# V32F20x_CM0 register map
File version: 1.0.1
CPU: CM0 r0p0, little endian, no MPU, no FPU, 2 interrupt priority bits
Registers are 32-bit, read-write, reset 0x0 unless marked. A register's access mark holds for its fields unless they carry their own. Offsets are from the block's base; [hi:lo] are bit positions; {n}, {i} and the like mark numbered series.

## CRYPT — CRYPT Peripheral Interface
Base 0x4120C000
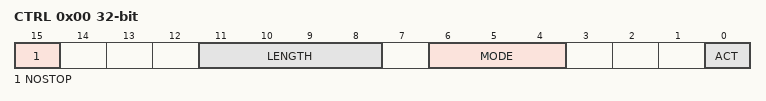
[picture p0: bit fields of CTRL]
0x00 CTRL — CRYPT control register.
  [15] NOSTOP — This register is used to control if the CPU will be stop by CRYPT engine when the CRYPT engine is busy and CPU read or write CRYPT engine register
  [11:8] LENGTH — This bit is used to control the VLI length of current operation
  [6:4] MODE — This register controls the operation mode of crypt engine
  [0] ACT — Write 1 to this bit will start an operation specified in the MODE register
0x04 PTRA — CRYPT pointer A register.
  [15:0] PTRA — This is the PTRA register of CRYPT controller
0x08 PTRB — CRYPT pointer B register.
  [15:0] PTRB — This is the PTRB register of CRYPT controller.
0x0C PTRO — CRYPT pointer O register.
  [15:0] PTRO — This is the PTRO register of CRYPT controller.
0x10 CARRY ro — CRYPT carry/borrow bit register.
  [0] CARRY — This bit represent the carry bit after add operation is done

## RETRAM — RETRAM Peripheral Interface
Base 0x41100000
{0x0+4i} RAM{i} (i=0..63) — PMU 32 bits Retention RAM 0~63
  [31:0] RAM — There is a 256 bytes 64x32 SRAM embedded in the PMU controller

## COMP — COMP Peripheral Interface
Base 0x41101800
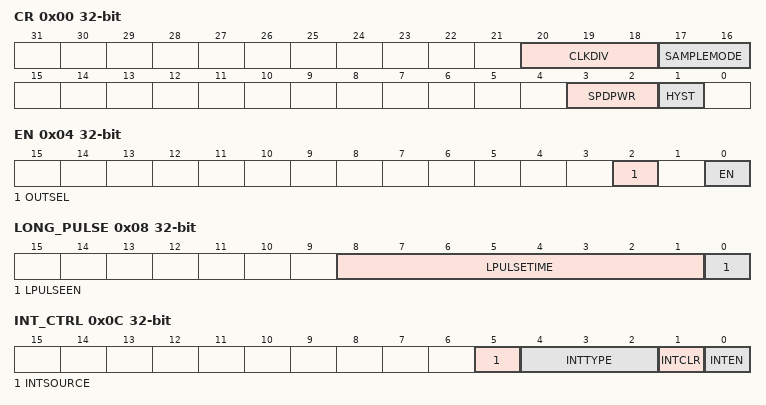
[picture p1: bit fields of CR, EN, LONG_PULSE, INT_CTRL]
0x00 CR — Control Register
  [20:18] CLKDIV — Filter clock divider
  [17:16] SAMPLEMODE — Control the filtering of the Analog Comparator output
  [3:2] SPDPWR — 00 Low speed Ultra low power Power consumption 2
  [1] HYST — 0: No Hysteresis Voltage
0x04 EN — Enable Register
  [2] OUTSEL — Comparator comparison select
  [0] EN — Enable Comparator
0x08 LONG_PULSE — Long pulse mode register
  [8:1] LPULSETIME — Desired time period of the long pulse.
  [0] LPULSEEN — Enable long pulse mode
0x0C INT_CTRL — Interrupt Control
  [5] INTSOURCE — Select which Analog comparator output filtered or unfiltered is used for interrupt detection
  [4:2] INTTYPE — Comparator interrupt type selector.
  [1] INTCLR — COMP interrupt clear.
  [0] INTEN — COMP interrupt enable.
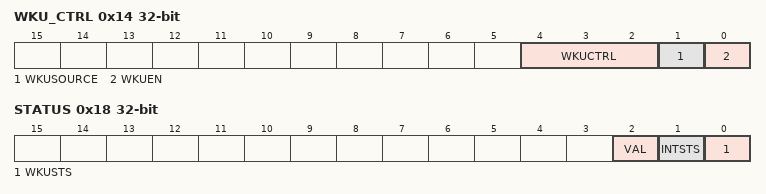
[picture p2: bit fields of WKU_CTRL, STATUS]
0x14 WKU_CTRL — Wake up control
  [4:2] WKUCTRL — Comparator wake up type selector.
  [1] WKUSOURCE — Select which Analog comparator output filtered our unfiltered is used for wake up detection
  [0] WKUEN — 1: Wake Up enable
0x18 STATUS
  [2] VAL — Comparator Output
  [1] INTSTS — Interrupt Status
  [0] WKUSTS — Wake-Up Status

## GPIOA — GPIOA Peripheral Interface
Base 0x41104000
Same registers: GPIOB 0x41104400, GPIOC 0x41104800, GPIOD 0x41104C00, GPIOE 0x41105000, GPIOF 0x41105400, GPIOG 0x41105800, GPIOH 0x41105C00, GPIOI 0x41106000
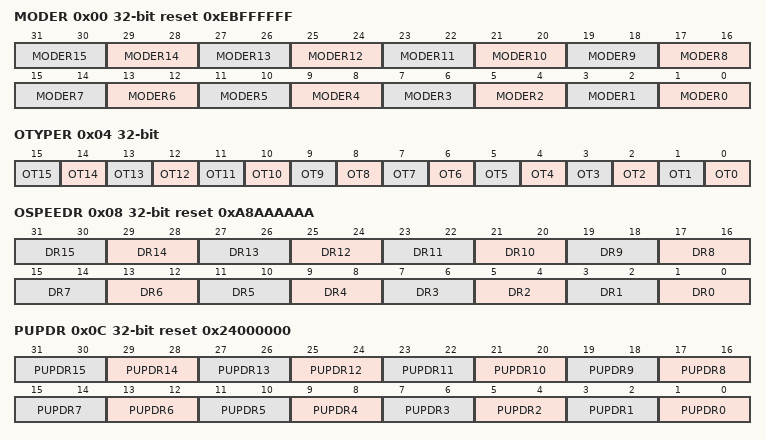
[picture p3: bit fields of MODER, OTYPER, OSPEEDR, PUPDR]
0x00 MODER reset 0xEBFFFFFF — GPIOx port mode register
  [2n+1:2n] MODER{n} (n=0..15) — These bits are written by software to configure the Px{n} direction mode
0x04 OTYPER — GPIO_OTYPER Abstract
  [n] OT{n} (n=0..15) — These bits are written by software to configure the output type of the Px{n} port
0x08 OSPEEDR reset 0xA8AAAAAA — GPIOx output drive strength
  [2n+1:2n] DR{n} (n=0..15) — Px{n} output drive strength
0x0C PUPDR reset 0x24000000 — GPIOx port pull-up and pull-down register
  [2n+1:2n] PUPDR{n} (n=0..15) — These bits are written by software to configure the Px{n} pull up or pull down
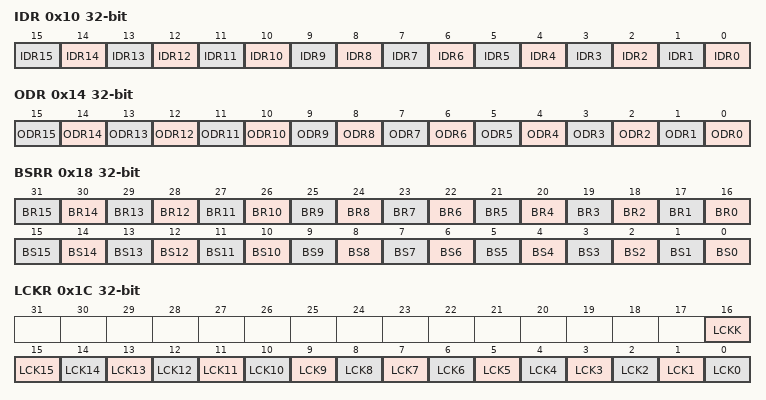
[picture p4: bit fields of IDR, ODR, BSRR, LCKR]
0x10 IDR ro — GPIOx port input data register
  [n] IDR{n} (n=0..15) — These bits are read only and can be accessed in word mode only
0x14 ODR — GPIOx port output data register
  [n] ODR{n} (n=0..15) — These bits can be read and written by software for Px{n}
0x18 BSRR — GPIOx port bit set/reset register
  [n+16] BR{n} (n=0..15) — This bit is write only
  [n] BS{n} (n=0..15) — This bit is write only
0x1C LCKR — GPIO_LCKR Abstract
  [16] LCKK — This bit can be read any time
  [n] LCK{n} (n=0..15) — Px{n} configure lock signal
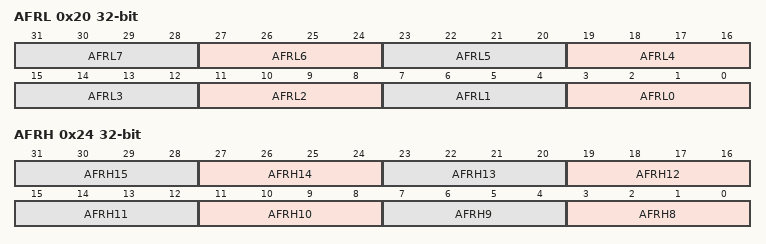
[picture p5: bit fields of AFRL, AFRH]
0x20 AFRL — Px0 to Px7 Alternate function selection
  [4n+3:4n] AFRL{n} (n=0..7) — Px{n} Alternate function selection
0x24 AFRH — Px8 to Px15 Alternate function selection
  [4n-29:4n-32] AFRH{n} (n=8..15) — Px{n} Alternate function selection

## EXTI — EXTI Peripheral Interface
Base 0x41106800
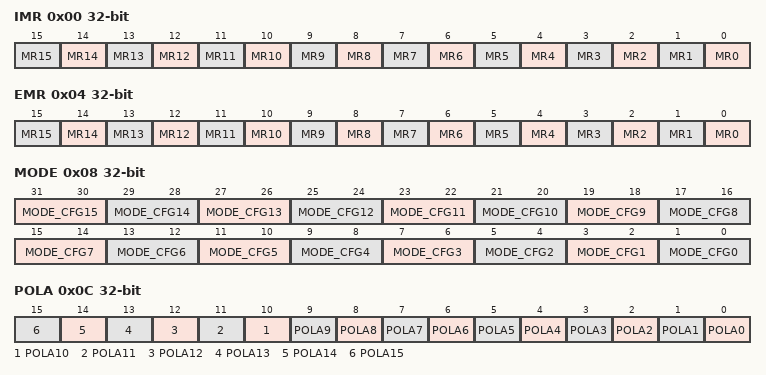
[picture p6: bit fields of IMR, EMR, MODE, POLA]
0x00 IMR — EXTI interrupt mask register
  [n] MR{n} (n=0..15) — Interrupt mask on line{n}
0x04 EMR — EXTI wakeup mask register
  [n] MR{n} (n=0..15) — Wakeup mask on line{n}
0x08 MODE — EXTI interrupt and wakerup mode configure register
  [31:30] MODE_CFG15 — The mode of line15 interrupt and wakeup configure:
  [29:28] MODE_CFG14 — The mode of line14 interrupt and wakeup configure:
  [27:26] MODE_CFG13 — The mode of line13 nterrupt and wakeup configure:
  [2n+1:2n] MODE_CFG{n} (n=4..12) — The mode of line{n} interrupt and wakeup configure:
  [7:6] MODE_CFG3 — The mode of linre3 interrupt and wakeup configure:
  [5:4] MODE_CFG2 — The mode of line2 interrupt and wakeup configure:
  [3:2] MODE_CFG1 — The mode of line1 interrupt and wakeup configure:
  [1:0] MODE_CFG0 — The mode of line0 interrupt and wakeup configure:
0x0C POLA — EXTI interrupt and wakerup polarity configure register
  [n] POLA{n} (n=0..15) — The polarity of line{n} interrupt and wakeup configure
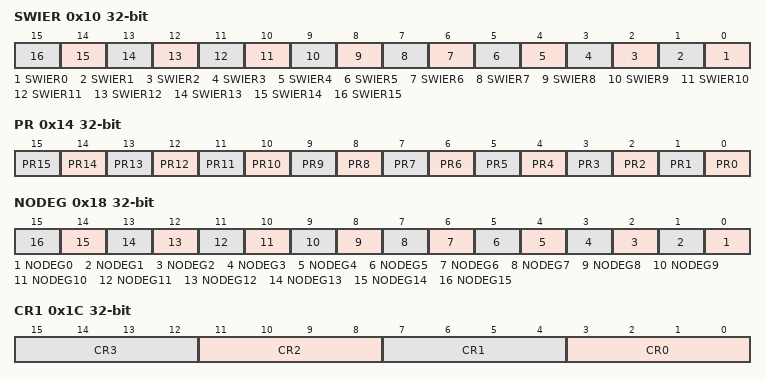
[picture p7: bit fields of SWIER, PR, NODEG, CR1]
0x10 SWIER — Interrupt software control register
  [n] SWIER{n} (n=0..15) — Software Interrupt on line{n}
0x14 PR — EXTI interrupt pending register
  [n] PR{n} (n=0..15) — Pending bit of line{n}
0x18 NODEG — External input signal deglitch control register
  [n] NODEG{n} (n=0..15) — Line{n} external input signal deglitch disable:
0x1C CR1 — EXTI input pin select register1
  [4n+3:4n] CR{n} (n=0..3) — EXTI line{n} input pin selection:
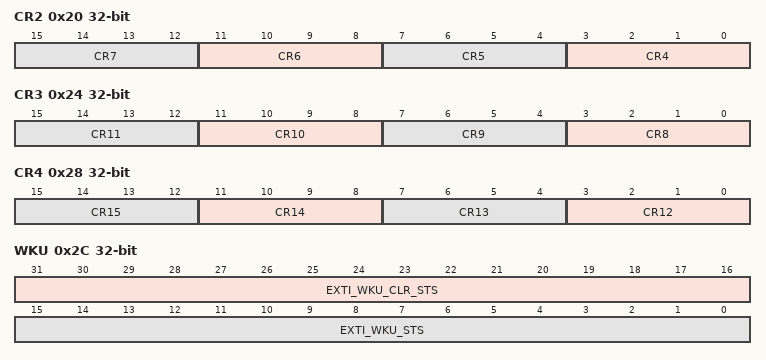
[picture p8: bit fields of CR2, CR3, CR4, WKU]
0x20 CR2 — EXTI input pin select register2
  [4n-13:4n-16] CR{n} (n=4..7) — EXTI line{n} input pin selection:
0x24 CR3 — EXTI input pin select register3
  [4n-29:4n-32] CR{n} (n=8..11) — EXTI line{n} input pin selection:
0x28 CR4 — EXTI input pin select register4
  [4n-45:4n-48] CR{n} (n=12..15) — EXTI line{n} input pin selection:
0x2C WKU — EXTI wakeup status and clear register
  [31:16] EXTI_WKU_CLR_STS — EXTI_WKU_STS clear status
  [15:0] EXTI_WKU_STS — 1: Corresponding EXTI wake up occured

## VGIO — VGIO Peripheral Interface
Base 0x41107000
{0x0+4i} BOTTOM{i} (i=0..31) — VGIO configure register on bottom side
  [31:0] BOTTOM
{0x100+4i} RIGHT{i} (i=0..31) — VGIO configure register on right side
  [31:0] RIGHT
{0x200+4i} TOP{i} (i=0..31) — VGIO configure register on top side
  [31:0] TOP
{0x300+4i} LEFT{i} (i=0..31) — VGIO configure register on left side
  [31:0] BOTTOM
